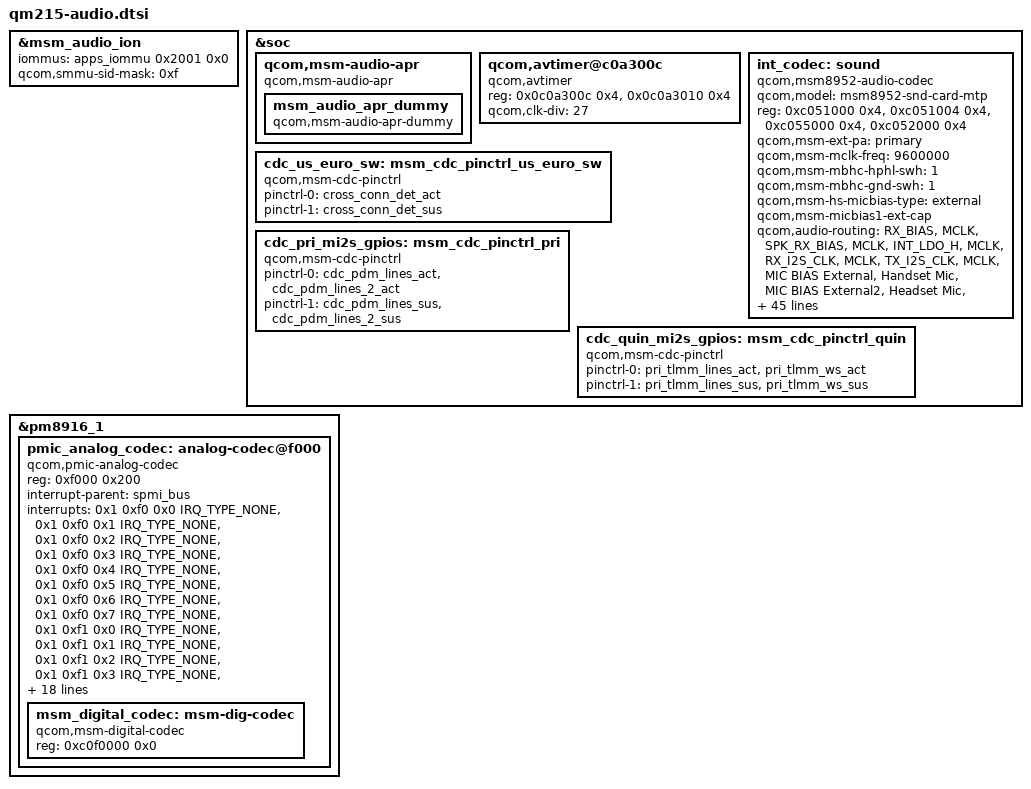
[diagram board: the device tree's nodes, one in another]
/*
 * Copyright (c) 2018, The Linux Foundation. All rights reserved.
 *
 * This program is free software; you can redistribute it and/or modify
 * it under the terms of the GNU General Public License version 2 and
 * only version 2 as published by the Free Software Foundation.
 *
 * This program is distributed in the hope that it will be useful,
 * but WITHOUT ANY WARRANTY; without even the implied warranty of
 * MERCHANTABILITY or FITNESS FOR A PARTICULAR PURPOSE.  See the
 * GNU General Public License for more details.
 */

#include "msm-audio-lpass.dtsi"

&msm_audio_ion {
	iommus = <&apps_iommu 0x2001 0x0>;
	qcom,smmu-sid-mask = /bits/ 64 <0xf>;
};

&soc {
	qcom,msm-audio-apr {
		compatible = "qcom,msm-audio-apr";
		msm_audio_apr_dummy {
			compatible = "qcom,msm-audio-apr-dummy";
		};
	};

	qcom,avtimer@c0a300c {
		compatible = "qcom,avtimer";
		reg = <0x0c0a300c 0x4>,
			<0x0c0a3010 0x4>;
		reg-names = "avtimer_lsb_addr", "avtimer_msb_addr";
		qcom,clk-div = <27>;
	};

	int_codec: sound {
		status = "okay";
		compatible = "qcom,msm8952-audio-codec";
		qcom,model = "msm8952-snd-card-mtp";
		reg = <0xc051000 0x4>,
			<0xc051004 0x4>,
			<0xc055000 0x4>,
			<0xc052000 0x4>;
		reg-names = "csr_gp_io_mux_mic_ctl",
			"csr_gp_io_mux_spkr_ctl",
			"csr_gp_io_lpaif_pri_pcm_pri_mode_muxsel",
			"csr_gp_io_mux_quin_ctl";

		qcom,msm-ext-pa = "primary";
		qcom,msm-mclk-freq = <9600000>;
		qcom,msm-mbhc-hphl-swh = <1>;
		qcom,msm-mbhc-gnd-swh = <1>;
		qcom,msm-hs-micbias-type = "external";
		qcom,msm-micbias1-ext-cap;

		qcom,audio-routing =
				"RX_BIAS", "MCLK",
				"SPK_RX_BIAS", "MCLK",
				"INT_LDO_H", "MCLK",
				"RX_I2S_CLK", "MCLK",
				"TX_I2S_CLK", "MCLK",
				"MIC BIAS External", "Handset Mic",
				"MIC BIAS External2", "Headset Mic",
				"MIC BIAS External", "Secondary Mic",
				"AMIC1", "MIC BIAS External",
				"AMIC2", "MIC BIAS External2",
				"AMIC3", "MIC BIAS External",
				"ADC1_IN", "ADC1_OUT",
				"ADC2_IN", "ADC2_OUT",
				"ADC3_IN", "ADC3_OUT",
				"PDM_IN_RX1", "PDM_OUT_RX1",
				"PDM_IN_RX2", "PDM_OUT_RX2",
				"PDM_IN_RX3", "PDM_OUT_RX3";

		qcom,pri-mi2s-gpios = <&cdc_pri_mi2s_gpios>;
		qcom,quin-mi2s-gpios = <&cdc_quin_mi2s_gpios>;

		asoc-platform = <&pcm0>, <&pcm1>, <&pcm2>, <&voip>, <&voice>,
				<&loopback>, <&compress>, <&hostless>,
				<&afe>, <&lsm>, <&routing>, <&pcm_noirq>;
		asoc-platform-names = "msm-pcm-dsp.0", "msm-pcm-dsp.1",
				"msm-pcm-dsp.2", "msm-voip-dsp",
				"msm-pcm-voice", "msm-pcm-loopback",
				"msm-compress-dsp", "msm-pcm-hostless",
				"msm-pcm-afe", "msm-lsm-client",
				"msm-pcm-routing", "msm-pcm-dsp-noirq";
		asoc-cpu = <&dai_pri_auxpcm>,
			<&dai_mi2s0>, <&dai_mi2s1>,
			<&dai_mi2s2>, <&dai_mi2s3>,
			<&dai_mi2s4>, <&dai_mi2s5>,
			<&sb_0_rx>, <&sb_0_tx>, <&sb_1_rx>, <&sb_1_tx>,
			<&sb_3_rx>, <&sb_3_tx>, <&sb_4_rx>, <&sb_4_tx>,
			<&bt_sco_rx>, <&bt_sco_tx>,
			<&int_fm_rx>, <&int_fm_tx>,
			<&afe_pcm_rx>, <&afe_pcm_tx>,
			<&afe_proxy_rx>, <&afe_proxy_tx>,
			<&incall_record_rx>, <&incall_record_tx>,
			<&incall_music_rx>, <&incall_music_2_rx>;

		asoc-cpu-names = "msm-dai-q6-auxpcm.1",
				"msm-dai-q6-mi2s.0", "msm-dai-q6-mi2s.1",
				"msm-dai-q6-mi2s.2", "msm-dai-q6-mi2s.3",
				"msm-dai-q6-mi2s.4", "msm-dai-q6-mi2s.6",
				"msm-dai-q6-dev.16384", "msmdai-q6-dev.16385",
				"msm-dai-q6-dev.16386", "msm-dai-q6-dev.16387",
				"msm-dai-q6-dev.16390", "msm-dai-q6-dev.16391",
				"msm-dai-q6-dev.16392", "msm-dai-q6-dev.16393",
				"msm-dai-q6-dev.12288", "msm-dai-q6-dev.12289",
				"msm-dai-q6-dev.12292", "msm-dai-q6-dev.12293",
				"msm-dai-q6-dev.224", "msm-dai-q6-dev.225",
				"msm-dai-q6-dev.241", "msm-dai-q6-dev.240",
				"msm-dai-q6-dev.32771", "msm-dai-q6-dev.32772",
				"msm-dai-q6-dev.32773", "msm-dai-q6-dev.32770";

		asoc-codec = <&stub_codec>, <&msm_digital_codec>,
				<&pmic_analog_codec>;
		asoc-codec-names = "msm-stub-codec.1", "msm-dig-codec",
					"analog-codec";
	};

	cdc_us_euro_sw: msm_cdc_pinctrl_us_euro_sw {
		compatible = "qcom,msm-cdc-pinctrl";
		pinctrl-names = "aud_active", "aud_sleep";
		pinctrl-0 = <&cross_conn_det_act>;
		pinctrl-1 = <&cross_conn_det_sus>;
	};

	cdc_pri_mi2s_gpios: msm_cdc_pinctrl_pri {
		compatible = "qcom,msm-cdc-pinctrl";
		pinctrl-names = "aud_active", "aud_sleep";
		pinctrl-0 = <&cdc_pdm_lines_act &cdc_pdm_lines_2_act>;
		pinctrl-1 = <&cdc_pdm_lines_sus &cdc_pdm_lines_2_sus>;
	};

	cdc_quin_mi2s_gpios: msm_cdc_pinctrl_quin {
		compatible = "qcom,msm-cdc-pinctrl";
		pinctrl-names = "aud_active", "aud_sleep";
		pinctrl-0 = <&pri_tlmm_lines_act &pri_tlmm_ws_act>;
		pinctrl-1 = <&pri_tlmm_lines_sus &pri_tlmm_ws_sus>;
	};
};

&pm8916_1 {
	pmic_analog_codec: analog-codec@f000 {
		status = "okay";
		compatible = "qcom,pmic-analog-codec";
		reg = <0xf000 0x200>;
		#address-cells = <2>;
		#size-cells = <0>;
		interrupt-parent = <&spmi_bus>;
		interrupts = <0x1 0xf0 0x0 IRQ_TYPE_NONE>,
			<0x1 0xf0 0x1 IRQ_TYPE_NONE>,
			<0x1 0xf0 0x2 IRQ_TYPE_NONE>,
			<0x1 0xf0 0x3 IRQ_TYPE_NONE>,
			<0x1 0xf0 0x4 IRQ_TYPE_NONE>,
			<0x1 0xf0 0x5 IRQ_TYPE_NONE>,
			<0x1 0xf0 0x6 IRQ_TYPE_NONE>,
			<0x1 0xf0 0x7 IRQ_TYPE_NONE>,
			<0x1 0xf1 0x0 IRQ_TYPE_NONE>,
			<0x1 0xf1 0x1 IRQ_TYPE_NONE>,
			<0x1 0xf1 0x2 IRQ_TYPE_NONE>,
			<0x1 0xf1 0x3 IRQ_TYPE_NONE>,
			<0x1 0xf1 0x4 IRQ_TYPE_NONE>,
			<0x1 0xf1 0x5 IRQ_TYPE_NONE>;
		interrupt-names = "spk_cnp_int",
				"spk_clip_int",
				"spk_ocp_int",
				"ins_rem_det1",
				"but_rel_det",
				"but_press_det",
				"ins_rem_det",
				"mbhc_int",
				"ear_ocp_int",
				"hphr_ocp_int",
				"hphl_ocp_det",
				"ear_cnp_int",
				"hphr_cnp_int",
				"hphl_cnp_int";

		cdc-vdd-pa-cp-supply = <&pm8916_s4>;
		qcom,cdc-vdd-pa-cp-voltage = <2050000 2050000>;
		qcom,cdc-vdd-pa-cp-current = <550000>;

		cdc-vdd-io-supply = <&pm8916_l5>;
		qcom,cdc-vdd-io-voltage = <1800000 1800000>;
		qcom,cdc-vdd-io-current = <5000>;

		cdc-vdda-h-supply = <&pm8916_l5>;
		qcom,cdc-vdda-h-voltage = <1800000 1800000>;
		qcom,cdc-vdda-h-current = <10000>;

		cdc-vdd-mic-bias-supply = <&pm8916_l13>;
		qcom,cdc-vdd-mic-bias-voltage = <3075000 3075000>;
		qcom,cdc-vdd-mic-bias-current = <5000>;

		qcom,cdc-mclk-clk-rate = <9600000>;

		qcom,cdc-static-supplies = "cdc-vdd-io",
					"cdc-vdd-pa-cp",
					"cdc-vdda-h";

		qcom,cdc-on-demand-supplies = "cdc-vdd-mic-bias";

		msm_digital_codec: msm-dig-codec {
			compatible = "qcom,msm-digital-codec";
			reg = <0xc0f0000 0x0>;
		};
	};
};
